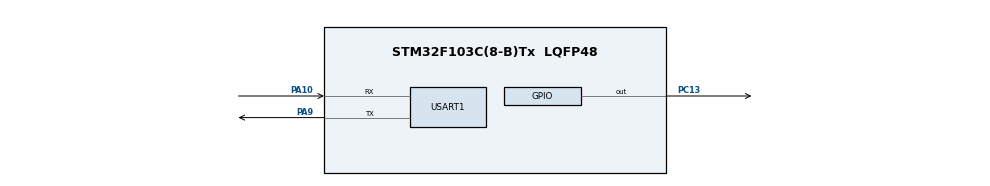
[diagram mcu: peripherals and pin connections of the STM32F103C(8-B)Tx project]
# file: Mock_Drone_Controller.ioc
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Mcu.Family=STM32F1
Mcu.Name=STM32F103C(8-B)Tx
Mcu.Package=LQFP48
NVIC.PriorityGroup=NVIC_PRIORITYGROUP_4
NVIC.USART1_IRQn=true\:0\:0\:false\:false\:true\:true\:true\:true
PA10.Mode=Asynchronous
PA10.Signal=USART1_RX
PA9.Mode=Asynchronous
PA9.Signal=USART1_TX
PC13-TAMPER-RTC.Signal=GPIO_Output
ProjectManager.HeapSize=0x200
ProjectManager.StackSize=0x400
ProjectManager.TargetToolchain=CMake
RCC.APB1Freq_Value=8000000
RCC.APB2Freq_Value=8000000
USART1.VirtualMode=VM_ASYNC
VP_SYS_VS_ND.Mode=No_Debug
board=custom

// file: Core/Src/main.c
/* USER CODE BEGIN Header */
/**
  ******************************************************************************
  * @file           : main.c
  * @brief          : Main program body
  ******************************************************************************
  * @attention
  *
  * Copyright (c) 2026 STMicroelectronics.
  * All rights reserved.
  *
  * This software is licensed under terms that can be found in the LICENSE file
  * in the root directory of this software component.
  * If no LICENSE file comes with this software, it is provided AS-IS.
  *
  ******************************************************************************
  */
/* USER CODE END Header */
#include "main.h"

/* USER CODE BEGIN Includes */
#include <string.h>

#include "vehicle_state.h"
#include "telemetry_generator.h"
#include "command_parser.h"
/* USER CODE END Includes */

/* USER CODE BEGIN PD */
#define COMMAND_BUFFER_SIZE 64
#define COMMAND_RESPONSE_BUFFER_SIZE 96
/* USER CODE END PD */

UART_HandleTypeDef huart1;

/* USER CODE BEGIN PV */
static VehicleState vehicle_state;
static char telemetry_buffer[128];

static uint8_t uart_rx_byte;
static char command_buffer[COMMAND_BUFFER_SIZE];
static volatile uint16_t command_buffer_index = 0;
static volatile uint8_t command_line_ready = 0;

static char command_response_buffer[COMMAND_RESPONSE_BUFFER_SIZE];
/* USER CODE END PV */

void SystemClock_Config(void);
static void MX_GPIO_Init(void);
static void MX_USART1_UART_Init(void);

int main(void)
{

  /* MCU Configuration--------------------------------------------------------*/

  /* Reset of all peripherals, Initializes the Flash interface and the Systick. */
  HAL_Init();

  /* USER CODE BEGIN Init */
  RCC->APB2ENR |= RCC_APB2ENR_IOPCEN;
  GPIOC->CRH &= ~(0xFU << 20);
  GPIOC->CRH |=  (0x2U << 20);

  // Turn LED on before SystemClock_Config
  GPIOC->BRR = GPIO_BRR_BR13;
  /* USER CODE END Init */

  /* Configure the system clock */
  SystemClock_Config();

  /* USER CODE BEGIN SysInit */
  // If this line is reached, LED turns off
  GPIOC->BSRR = GPIO_BSRR_BS13;
  /* USER CODE END SysInit */

  /* Initialize all configured peripherals */
  MX_GPIO_Init();
  MX_USART1_UART_Init();
  /* USER CODE BEGIN 2 */
  VehicleState_Init(&vehicle_state);
  vehicle_state.armed = 0;
  vehicle_state.mode = MODE_AUTO;
  HAL_UART_Receive_IT(&huart1, &uart_rx_byte, 1);
  /* USER CODE END 2 */

  /* Infinite loop */
  /* USER CODE BEGIN WHILE */
  while (1)
  {
    if (command_line_ready)
    {
        char local_command[COMMAND_BUFFER_SIZE];

        // global disable interrupts to avoid possible data race condition.
        __disable_irq();

        /*for (uint16_t i = 0; i < COMMAND_BUFFER_SIZE; ++i)
        {
            local_command[i] = command_buffer[i];

            if (command_buffer[i] == '\0')
            {
                break;
            }
        }*/

        strncpy(local_command, command_buffer, COMMAND_BUFFER_SIZE);
        local_command[COMMAND_BUFFER_SIZE-1] = '\0';

        command_buffer_index = 0;
        command_buffer[0] = '\0';
        command_line_ready = 0;

        // global enable interrupts
        __enable_irq();

        //CommandParser_ApplyLine(local_command, &vehicle_state);

        CommandResult result = CommandParser_Handle(local_command, &vehicle_state, command_response_buffer, sizeof(command_response_buffer));
        if (result != CMD_RESULT_OK)
        {
            // TODO deal with the error
        }

        if (command_response_buffer[0] != '\0') {
          HAL_UART_Transmit(&huart1, (uint8_t*)command_response_buffer, strlen(command_response_buffer), 100);
        }
    }
    /* USER CODE END WHILE */

    /* USER CODE BEGIN 3 */
    VehicleState_Update(&vehicle_state, 0.5f);

    TelemetryGenerator_BuildPacket(
      &vehicle_state,
      telemetry_buffer,
      sizeof(telemetry_buffer)
    );

    HAL_UART_Transmit(
      &huart1,
      (uint8_t*)telemetry_buffer,
      strlen(telemetry_buffer),
      100
    );

    HAL_GPIO_TogglePin(GPIOC, GPIO_PIN_13);
    HAL_Delay(500);
  }
  /* USER CODE END 3 */
}

void SystemClock_Config(void)
{
  RCC_OscInitTypeDef RCC_OscInitStruct = {0};
  RCC_ClkInitTypeDef RCC_ClkInitStruct = {0};

  /** Initializes the RCC Oscillators according to the specified parameters
  * in the RCC_OscInitTypeDef structure.
  */
  RCC_OscInitStruct.OscillatorType = RCC_OSCILLATORTYPE_HSI;
  RCC_OscInitStruct.HSIState = RCC_HSI_ON;
  RCC_OscInitStruct.HSICalibrationValue = RCC_HSICALIBRATION_DEFAULT;
  RCC_OscInitStruct.PLL.PLLState = RCC_PLL_NONE;
  if (HAL_RCC_OscConfig(&RCC_OscInitStruct) != HAL_OK)
  {
    Error_Handler();
  }

  /** Initializes the CPU, AHB and APB buses clocks
  */
  RCC_ClkInitStruct.ClockType = RCC_CLOCKTYPE_HCLK|RCC_CLOCKTYPE_SYSCLK
                              |RCC_CLOCKTYPE_PCLK1|RCC_CLOCKTYPE_PCLK2;
  RCC_ClkInitStruct.SYSCLKSource = RCC_SYSCLKSOURCE_HSI;
  RCC_ClkInitStruct.AHBCLKDivider = RCC_SYSCLK_DIV1;
  RCC_ClkInitStruct.APB1CLKDivider = RCC_HCLK_DIV1;
  RCC_ClkInitStruct.APB2CLKDivider = RCC_HCLK_DIV1;

  if (HAL_RCC_ClockConfig(&RCC_ClkInitStruct, FLASH_LATENCY_0) != HAL_OK)
  {
    Error_Handler();
  }
}

static void MX_USART1_UART_Init(void)
{

  huart1.Instance = USART1;
  huart1.Init.BaudRate = 115200;
  huart1.Init.WordLength = UART_WORDLENGTH_8B;
  huart1.Init.StopBits = UART_STOPBITS_1;
  huart1.Init.Parity = UART_PARITY_NONE;
  huart1.Init.Mode = UART_MODE_TX_RX;
  huart1.Init.HwFlowCtl = UART_HWCONTROL_NONE;
  huart1.Init.OverSampling = UART_OVERSAMPLING_16;
  if (HAL_UART_Init(&huart1) != HAL_OK)
  {
    Error_Handler();
  }

}

static void MX_GPIO_Init(void)
{
  GPIO_InitTypeDef GPIO_InitStruct = {0};

  /* GPIO Ports Clock Enable */
  __HAL_RCC_GPIOC_CLK_ENABLE();
  __HAL_RCC_GPIOA_CLK_ENABLE();

  /*Configure GPIO pin Output Level */
  HAL_GPIO_WritePin(GPIOC, GPIO_PIN_13, GPIO_PIN_RESET);

  /*Configure GPIO pin : PC13 */
  GPIO_InitStruct.Pin = GPIO_PIN_13;
  GPIO_InitStruct.Mode = GPIO_MODE_OUTPUT_PP;
  GPIO_InitStruct.Pull = GPIO_NOPULL;
  GPIO_InitStruct.Speed = GPIO_SPEED_FREQ_LOW;
  HAL_GPIO_Init(GPIOC, &GPIO_InitStruct);

}

/* USER CODE BEGIN 4 */
void HAL_UART_RxCpltCallback(UART_HandleTypeDef* huart)
{
    if (huart->Instance != USART1)
    {
        return;
    }

    if (!command_line_ready)
    {
        if (uart_rx_byte == '\n')
        {
            command_buffer[command_buffer_index] = '\0';
            command_line_ready = 1;
        }
        else if (uart_rx_byte != '\r')
        {
            if (command_buffer_index < COMMAND_BUFFER_SIZE - 1)
            {
                command_buffer[command_buffer_index] = (char)uart_rx_byte;
                command_buffer_index++;
            }
            else
            {
                command_buffer_index = 0;
                command_buffer[0] = '\0';
            }
        }
    }

    HAL_UART_Receive_IT(&huart1, &uart_rx_byte, 1);
}

void HAL_UART_ErrorCallback(UART_HandleTypeDef* huart)
{
    if (huart->Instance == USART1)
    {
        HAL_UART_Receive_IT(&huart1, &uart_rx_byte, 1);
    }
}

/* USER CODE END 4 */

void Error_Handler(void)
{
  /* USER CODE BEGIN Error_Handler_Debug */
  /* User can add his own implementation to report the HAL error return state */
  __disable_irq();

    RCC->APB2ENR |= RCC_APB2ENR_IOPCEN;

    GPIOC->CRH &= ~(0xFU << 20);
    GPIOC->CRH |=  (0x2U << 20);

    while (1)
    {
        GPIOC->BRR = GPIO_BRR_BR13;   // LED ON, active-low on many Blue Pills
        for (volatile int i = 0; i < 200000; ++i) {}

        GPIOC->BSRR = GPIO_BSRR_BS13; // LED OFF
        for (volatile int i = 0; i < 200000; ++i) {}
    }
  /* USER CODE END Error_Handler_Debug */
}
